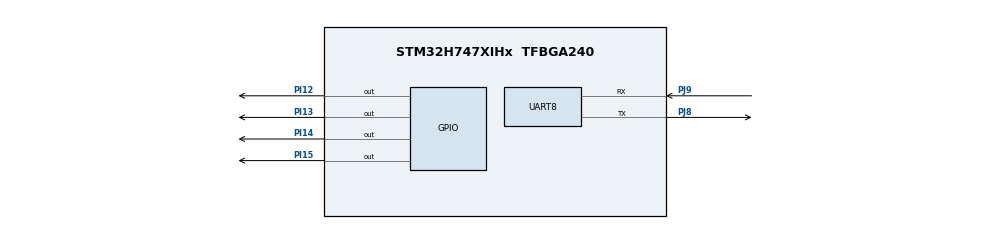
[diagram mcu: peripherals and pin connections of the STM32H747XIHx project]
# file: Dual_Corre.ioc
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Mcu.Family=STM32H7
RCC.CortexFreq_Value=480000000
PJ9.Mode=Asynchronous
RCC.HPRE=RCC_HCLK_DIV2
PH0-OSC_IN\ (PH0).PinAttribute=CortexM7
PH0-OSC_IN\ (PH0).Signal=RCC_OSC_IN
RCC.PLLFRACN=0
RCC.PLL2FRACN=0
RCC.SYSCLKSource=RCC_SYSCLKSOURCE_PLLCLK
ProjectManager.StackSize=0x400
RCC.HCLKFreq_Value=240000000
PI13.Signal=GPIO_Output
PH1-OSC_OUT\ (PH1).Mode=HSE-External-Oscillator
RCC.DIVM3=5
RCC.DIVM2=5
RCC.DIVM1=5
NVIC2.PriorityGroup=NVIC_PRIORITYGROUP_4
PI12.PinAttribute=CortexM4
VP_SYS_M4_VS_Systick.Mode=SysTick
CortexM7.Pins=PI14,PI15
CortexM7.IPs=BDMA\:I,CORTEX_M7\:I,DEBUG\:I,DMA\:I,FATFS_M7\:I,FREERTOS_M7\:I,IWDG1\:I,MDMA\:I,NVIC1\:I,OPENAMP_M7\:I,PDM2PCM_M7\:I,PWR\:I,RCC\:I,RESMGR_UTILITY\:I,SYS\:I,USB_DEVICE_M7\:I,USB_HOST_M7\:I,VREFBUF\:I,WWDG1\:I,UART8\:I
RCC.APB3Freq_Value=120000000
Mcu.Package=TFBGA240
PJ9.PinAttribute=CortexM7
PJ9.Signal=UART8_RX
RCC.PLL3FRACN=0
RCC.D1PPRE=RCC_APB3_DIV2
RCC.APB4Freq_Value=120000000
PH0-OSC_IN\ (PH0).Mode=HSE-External-Oscillator
RCC.SupplySource=PWR_DIRECT_SMPS_SUPPLY
PH1-OSC_OUT\ (PH1).PinAttribute=CortexM7
NVIC1.UART8_IRQn=true\:0\:0\:false\:false\:true\:true\:true
RCC.PLLSourceVirtual=RCC_PLLSOURCE_HSE
PJ8.Mode=Asynchronous
PI14.Signal=GPIO_Output
CortexM4.Pins=PI12,PI13
PI15.PinAttribute=CortexM7
PI14.PinAttribute=CortexM7
NVIC1.PriorityGroup=NVIC_PRIORITYGROUP_4
RCC.D2PPRE2=RCC_APB2_DIV2
PI12.Signal=GPIO_Output
RCC.D2PPRE1=RCC_APB1_DIV2
RCC.PWR_Regulator_Voltage_Scale=PWR_REGULATOR_VOLTAGE_SCALE0
PJ8.PinAttribute=CortexM7
PH1-OSC_OUT\ (PH1).Signal=RCC_OSC_OUT
SYS.userName=SYS_M7
ProjectManager.TargetToolchain=STM32CubeIDE
PI13.PinAttribute=CortexM4
RCC.DIVN3=192
RCC.DIVN2=192
RCC.DIVN1=192
RCC.USBFreq_Value=480000000
board=custom
RCC.APB2Freq_Value=120000000
RCC.ADCFreq_Value=480000000
Mcu.Name=STM32H747XIHx
RCC.SYSCLKFreq_VALUE=480000000
PJ8.Signal=UART8_TX
ProjectManager.HeapSize=0x200
PI15.Signal=GPIO_Output
RCC.D3PPRE=RCC_APB4_DIV2
RCC.APB1Freq_Value=120000000
CortexM4.IPs=BDMA,CORTEX_M4\:I,DEBUG,DMA,FATFS_M4\:I,FREERTOS_M4\:I,IWDG2\:I,MDMA,NVIC2\:I,OPENAMP_M4\:I,PDM2PCM_M4\:I,PWR,RCC,RESMGR_UTILITY,SYS_M4\:I,USB_DEVICE_M4\:I,USB_HOST_M4\:I,VREFBUF,WWDG2\:I

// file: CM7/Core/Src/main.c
/* USER CODE BEGIN Header */
/**
  ******************************************************************************
  * @file           : main.c
  * @brief          : Main program body
  ******************************************************************************
  * @attention
  *
  * <h2><center>&copy; Copyright (c) 2021 STMicroelectronics.
  * All rights reserved.</center></h2>
  *
  * This software component is licensed by ST under BSD 3-Clause license,
  * the "License"; You may not use this file except in compliance with the
  * License. You may obtain a copy of the License at:
  *                        opensource.org/licenses/BSD-3-Clause
  *
  ******************************************************************************
  */
/* USER CODE END Header */
#include "main.h"
#include <stdio.h>
#include <string.h>

/* USER CODE BEGIN PD */

#ifndef HSEM_ID_0
#define HSEM_ID_0 (0U) /* HW semaphore 0*/
#endif
/* USER CODE END PD */

/* USER CODE BEGIN PM */
struct shared_data
{
	uint8_t sts_4to7; // status: 0 = empty, 1 = has data, 2 = locked (CM4-CM7)
	uint8_t sts_7to4; // status: 0 = empty, 1 = has data, 2 = locked (CM7-CM4)
	uint32_t M4toM7[64]; // 256 bytes from CM4 to CM7
	uint32_t M7toM4[64]; // 256 bytes from CM7 to CM4
};

// pointer to shared_data struct (inter-core buffers and status)
volatile struct shared_data * const xfr_ptr = (struct shared_data *)0x20000000;
/* USER CODE END PM */

UART_HandleTypeDef huart8;

/* USER CODE BEGIN PV */
uint8_t *send_data = (uint8_t *)0x20000000;
/* USER CODE END PV */

void SystemClock_Config(void);
static void MX_GPIO_Init(void);
static void MX_UART8_Init(void);
/* USER CODE BEGIN PFP */
int __io_putchar (int ch) {
	uint8_t c = ch;
	HAL_UART_Transmit(&huart8, &c, 1, 1000);
	return ch;
}
/* USER CODE END PFP */

int main(void)
{
/* USER CODE BEGIN Boot_Mode_Sequence_0 */
  int32_t timeout;
/* USER CODE END Boot_Mode_Sequence_0 */

/* USER CODE BEGIN Boot_Mode_Sequence_1 */
  /* Wait until CPU2 boots and enters in stop mode or timeout*/
  timeout = 0xFFFF;
  while((__HAL_RCC_GET_FLAG(RCC_FLAG_D2CKRDY) != RESET) && (timeout-- > 0));
  if ( timeout < 0 )
  {
  Error_Handler();
  }
/* USER CODE END Boot_Mode_Sequence_1 */
  /* MCU Configuration--------------------------------------------------------*/

  /* Reset of all peripherals, Initializes the Flash interface and the Systick. */
  HAL_Init();

  /* Configure the system clock */
  SystemClock_Config();
/* USER CODE BEGIN Boot_Mode_Sequence_2 */
/* When system initialization is finished, Cortex-M7 will release Cortex-M4 by means of
HSEM notification */
/*HW semaphore Clock enable*/
__HAL_RCC_HSEM_CLK_ENABLE();
/*Take HSEM */
HAL_HSEM_FastTake(HSEM_ID_0);
/*Release HSEM in order to notify the CPU2(CM4)*/
HAL_HSEM_Release(HSEM_ID_0,0);
/* wait until CPU2 wakes up from stop mode */
timeout = 0xFFFF;
while((__HAL_RCC_GET_FLAG(RCC_FLAG_D2CKRDY) == RESET) && (timeout-- > 0));
if ( timeout < 0 )
{
Error_Handler();
}
/* USER CODE END Boot_Mode_Sequence_2 */

  /* Initialize all configured peripherals */
  MX_GPIO_Init();
  MX_UART8_Init();

  /* Infinite loop */
  while (1)
  {
	  printf(" WIZnet chip: %d \r\n",*send_data);
	  HAL_Delay(2000);
  }
}

void SystemClock_Config(void)
{
  RCC_OscInitTypeDef RCC_OscInitStruct = {0};
  RCC_ClkInitTypeDef RCC_ClkInitStruct = {0};

  /** Supply configuration update enable
  */
  HAL_PWREx_ConfigSupply(PWR_DIRECT_SMPS_SUPPLY);
  /** Configure the main internal regulator output voltage
  */
  __HAL_PWR_VOLTAGESCALING_CONFIG(PWR_REGULATOR_VOLTAGE_SCALE0);

  while(!__HAL_PWR_GET_FLAG(PWR_FLAG_VOSRDY)) {}
  /** Initializes the RCC Oscillators according to the specified parameters
  * in the RCC_OscInitTypeDef structure.
  */
  RCC_OscInitStruct.OscillatorType = RCC_OSCILLATORTYPE_HSE;
  RCC_OscInitStruct.HSEState = RCC_HSE_ON;
  RCC_OscInitStruct.PLL.PLLState = RCC_PLL_ON;
  RCC_OscInitStruct.PLL.PLLSource = RCC_PLLSOURCE_HSE;
  RCC_OscInitStruct.PLL.PLLM = 5;
  RCC_OscInitStruct.PLL.PLLN = 192;
  RCC_OscInitStruct.PLL.PLLP = 2;
  RCC_OscInitStruct.PLL.PLLQ = 2;
  RCC_OscInitStruct.PLL.PLLR = 2;
  RCC_OscInitStruct.PLL.PLLRGE = RCC_PLL1VCIRANGE_2;
  RCC_OscInitStruct.PLL.PLLVCOSEL = RCC_PLL1VCOWIDE;
  RCC_OscInitStruct.PLL.PLLFRACN = 0;
  if (HAL_RCC_OscConfig(&RCC_OscInitStruct) != HAL_OK)
  {
    Error_Handler();
  }
  /** Initializes the CPU, AHB and APB buses clocks
  */
  RCC_ClkInitStruct.ClockType = RCC_CLOCKTYPE_HCLK|RCC_CLOCKTYPE_SYSCLK
                              |RCC_CLOCKTYPE_PCLK1|RCC_CLOCKTYPE_PCLK2
                              |RCC_CLOCKTYPE_D3PCLK1|RCC_CLOCKTYPE_D1PCLK1;
  RCC_ClkInitStruct.SYSCLKSource = RCC_SYSCLKSOURCE_PLLCLK;
  RCC_ClkInitStruct.SYSCLKDivider = RCC_SYSCLK_DIV1;
  RCC_ClkInitStruct.AHBCLKDivider = RCC_HCLK_DIV2;
  RCC_ClkInitStruct.APB3CLKDivider = RCC_APB3_DIV2;
  RCC_ClkInitStruct.APB1CLKDivider = RCC_APB1_DIV2;
  RCC_ClkInitStruct.APB2CLKDivider = RCC_APB2_DIV2;
  RCC_ClkInitStruct.APB4CLKDivider = RCC_APB4_DIV2;

  if (HAL_RCC_ClockConfig(&RCC_ClkInitStruct, FLASH_LATENCY_4) != HAL_OK)
  {
    Error_Handler();
  }
}

static void MX_UART8_Init(void)
{

  huart8.Instance = UART8;
  huart8.Init.BaudRate = 115200;
  huart8.Init.WordLength = UART_WORDLENGTH_8B;
  huart8.Init.StopBits = UART_STOPBITS_1;
  huart8.Init.Parity = UART_PARITY_NONE;
  huart8.Init.Mode = UART_MODE_TX_RX;
  huart8.Init.HwFlowCtl = UART_HWCONTROL_NONE;
  huart8.Init.OverSampling = UART_OVERSAMPLING_16;
  huart8.Init.OneBitSampling = UART_ONE_BIT_SAMPLE_DISABLE;
  huart8.Init.ClockPrescaler = UART_PRESCALER_DIV1;
  huart8.AdvancedInit.AdvFeatureInit = UART_ADVFEATURE_NO_INIT;
  if (HAL_UART_Init(&huart8) != HAL_OK)
  {
    Error_Handler();
  }
  if (HAL_UARTEx_SetTxFifoThreshold(&huart8, UART_TXFIFO_THRESHOLD_1_8) != HAL_OK)
  {
    Error_Handler();
  }
  if (HAL_UARTEx_SetRxFifoThreshold(&huart8, UART_RXFIFO_THRESHOLD_1_8) != HAL_OK)
  {
    Error_Handler();
  }
  if (HAL_UARTEx_DisableFifoMode(&huart8) != HAL_OK)
  {
    Error_Handler();
  }

}

static void MX_GPIO_Init(void)
{
  GPIO_InitTypeDef GPIO_InitStruct = {0};

  /* GPIO Ports Clock Enable */
  __HAL_RCC_GPIOI_CLK_ENABLE();
  __HAL_RCC_GPIOH_CLK_ENABLE();
  __HAL_RCC_GPIOJ_CLK_ENABLE();

  /*Configure GPIO pin Output Level */
  HAL_GPIO_WritePin(GPIOI, GPIO_PIN_14|GPIO_PIN_15, GPIO_PIN_RESET);

  /*Configure GPIO pins : PI14 PI15 */
  GPIO_InitStruct.Pin = GPIO_PIN_14|GPIO_PIN_15;
  GPIO_InitStruct.Mode = GPIO_MODE_OUTPUT_PP;
  GPIO_InitStruct.Pull = GPIO_NOPULL;
  GPIO_InitStruct.Speed = GPIO_SPEED_FREQ_LOW;
  HAL_GPIO_Init(GPIOI, &GPIO_InitStruct);

}

void Error_Handler(void)
{
  /* USER CODE BEGIN Error_Handler_Debug */
  /* User can add his own implementation to report the HAL error return state */
//  __disable_irq();
//  while (1)
//  {
//  }
  /* USER CODE END Error_Handler_Debug */
}

/************************ (C) COPYRIGHT STMicroelectronics *****END OF FILE****/
